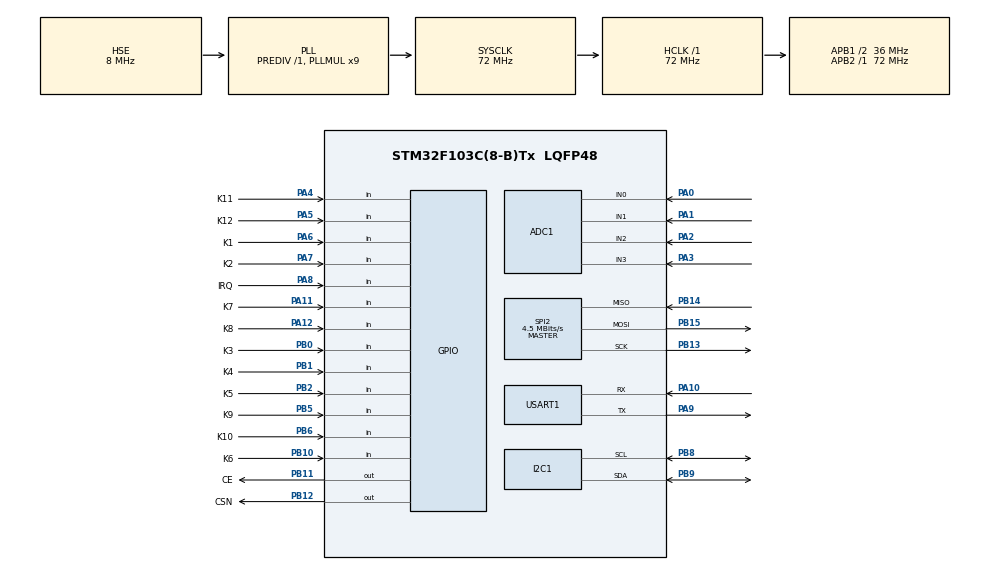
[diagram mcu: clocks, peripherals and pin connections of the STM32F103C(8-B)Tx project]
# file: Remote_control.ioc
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ADC1.Channel-0\#ChannelRegularConversion=ADC_CHANNEL_0
ADC1.Channel-1\#ChannelRegularConversion=ADC_CHANNEL_1
ADC1.Channel-2\#ChannelRegularConversion=ADC_CHANNEL_2
ADC1.Channel-3\#ChannelRegularConversion=ADC_CHANNEL_3
ADC1.ContinuousConvMode=ENABLE
ADC1.NbrOfConversion=4
ADC1.NbrOfConversionFlag=1
ADC1.Rank-0\#ChannelRegularConversion=1
ADC1.Rank-1\#ChannelRegularConversion=2
ADC1.Rank-2\#ChannelRegularConversion=3
ADC1.Rank-3\#ChannelRegularConversion=4
ADC1.SamplingTime-0\#ChannelRegularConversion=ADC_SAMPLETIME_55CYCLES_5
ADC1.SamplingTime-1\#ChannelRegularConversion=ADC_SAMPLETIME_55CYCLES_5
ADC1.SamplingTime-2\#ChannelRegularConversion=ADC_SAMPLETIME_55CYCLES_5
ADC1.SamplingTime-3\#ChannelRegularConversion=ADC_SAMPLETIME_55CYCLES_5
ADC1.master=1
Dma.ADC1.1.Direction=DMA_PERIPH_TO_MEMORY
Dma.ADC1.1.Instance=DMA1_Channel1
Dma.ADC1.1.MemDataAlignment=DMA_MDATAALIGN_HALFWORD
Dma.ADC1.1.MemInc=DMA_MINC_ENABLE
Dma.ADC1.1.Mode=DMA_CIRCULAR
Dma.ADC1.1.PeriphDataAlignment=DMA_PDATAALIGN_HALFWORD
Dma.ADC1.1.PeriphInc=DMA_PINC_DISABLE
Dma.ADC1.1.Priority=DMA_PRIORITY_LOW
Dma.Request0=USART1_RX
Dma.Request1=ADC1
Dma.USART1_RX.0.Direction=DMA_PERIPH_TO_MEMORY
Dma.USART1_RX.0.Instance=DMA1_Channel5
Dma.USART1_RX.0.MemDataAlignment=DMA_MDATAALIGN_BYTE
Dma.USART1_RX.0.MemInc=DMA_MINC_ENABLE
Dma.USART1_RX.0.Mode=DMA_CIRCULAR
Dma.USART1_RX.0.PeriphDataAlignment=DMA_PDATAALIGN_BYTE
Dma.USART1_RX.0.PeriphInc=DMA_PINC_DISABLE
Dma.USART1_RX.0.Priority=DMA_PRIORITY_LOW
I2C1.I2C_Mode=I2C_Fast
IWDG.Prescaler=IWDG_PRESCALER_16
IWDG.Reload=2500
Mcu.Family=STM32F1
Mcu.Name=STM32F103C(8-B)Tx
Mcu.Package=LQFP48
NVIC.DMA1_Channel1_IRQn=true\:0\:0\:false\:false\:true\:false\:true\:true
NVIC.DMA1_Channel5_IRQn=true\:0\:0\:false\:false\:true\:false\:true\:true
NVIC.PriorityGroup=NVIC_PRIORITYGROUP_4
NVIC.TIM1_UP_IRQn=true\:15\:0\:false\:false\:true\:true\:true\:true
NVIC.TIM2_IRQn=true\:0\:0\:false\:false\:true\:true\:true\:true
NVIC.USART1_IRQn=true\:0\:0\:false\:false\:true\:true\:true\:true
PA0-WKUP.Signal=ADCx_IN0
PA1.Signal=ADCx_IN1
PA10.Mode=Asynchronous
PA10.Signal=USART1_RX
PA11.GPIO_Label=K7
PA11.GPIO_Mode=GPIO_MODE_INPUT
PA11.GPIO_PuPd=GPIO_PULLUP
PA11.Signal=GPIO_Input
PA12.GPIO_Label=K8
PA12.GPIO_Mode=GPIO_MODE_INPUT
PA12.GPIO_PuPd=GPIO_PULLUP
PA12.Signal=GPIO_Input
PA13.Mode=Serial_Wire
PA13.Signal=SYS_JTMS-SWDIO
PA14.Mode=Serial_Wire
PA14.Signal=SYS_JTCK-SWCLK
PA2.Signal=ADCx_IN2
PA3.Signal=ADCx_IN3
PA4.GPIO_Label=K11
PA4.Signal=GPIO_Input
PA5.GPIO_Label=K12
PA5.Signal=GPIO_Input
PA6.GPIO_Label=K1
PA6.GPIO_Mode=GPIO_MODE_INPUT
PA6.GPIO_PuPd=GPIO_PULLUP
PA6.Signal=GPIO_Input
PA7.GPIO_Label=K2
PA7.GPIO_Mode=GPIO_MODE_INPUT
PA7.GPIO_PuPd=GPIO_PULLUP
PA7.Signal=GPIO_Input
PA8.GPIO_Label=IRQ
PA8.GPIO_Mode=GPIO_MODE_INPUT
PA8.GPIO_PuPd=GPIO_NOPULL
PA8.Signal=GPIO_Input
PA9.Mode=Asynchronous
PA9.Signal=USART1_TX
PB0.GPIO_Label=K3
PB0.GPIO_Mode=GPIO_MODE_INPUT
PB0.GPIO_PuPd=GPIO_PULLUP
PB0.Signal=GPIO_Input
PB1.GPIO_Label=K4
PB1.GPIO_Mode=GPIO_MODE_INPUT
PB1.GPIO_PuPd=GPIO_PULLUP
PB1.Signal=GPIO_Input
PB10.GPIO_Label=K6
PB10.GPIO_Mode=GPIO_MODE_INPUT
PB10.GPIO_PuPd=GPIO_PULLUP
PB10.Signal=GPIO_Input
PB11.GPIO_Label=CE
PB11.Signal=GPIO_Output
PB12.GPIO_Label=CSN
PB12.PinState=GPIO_PIN_SET
PB12.Signal=GPIO_Output
PB13.Mode=Full_Duplex_Master
PB13.Signal=SPI2_SCK
PB14.Mode=Full_Duplex_Master
PB14.Signal=SPI2_MISO
PB15.Mode=Full_Duplex_Master
PB15.Signal=SPI2_MOSI
PB2.GPIO_Label=K5
PB2.GPIO_Mode=GPIO_MODE_INPUT
PB2.GPIO_PuPd=GPIO_PULLUP
PB2.Signal=GPIO_Input
PB5.GPIO_Label=K9
PB5.GPIO_Mode=GPIO_MODE_INPUT
PB5.GPIO_PuPd=GPIO_PULLUP
PB5.Signal=GPIO_Input
PB6.GPIO_Label=K10
PB6.GPIO_Mode=GPIO_MODE_INPUT
PB6.GPIO_PuPd=GPIO_PULLUP
PB6.Signal=GPIO_Input
PB8.Mode=I2C
PB8.Signal=I2C1_SCL
PB9.Mode=I2C
PB9.Signal=I2C1_SDA
PD0-OSC_IN.Mode=HSE-External-Oscillator
PD0-OSC_IN.Signal=RCC_OSC_IN
PD1-OSC_OUT.Mode=HSE-External-Oscillator
PD1-OSC_OUT.Signal=RCC_OSC_OUT
ProjectManager.HeapSize=0x200
ProjectManager.StackSize=0x400
ProjectManager.TargetToolchain=MDK-ARM V5.32
RCC.ADCPresc=RCC_ADCPCLK2_DIV6
RCC.AHBFreq_Value=72000000
RCC.APB1CLKDivider=RCC_HCLK_DIV2
RCC.APB1Freq_Value=36000000
RCC.APB1TimFreq_Value=72000000
RCC.APB2Freq_Value=72000000
RCC.APB2TimFreq_Value=72000000
RCC.HCLKFreq_Value=72000000
RCC.PLLMUL=RCC_PLL_MUL9
RCC.PLLSourceVirtual=RCC_PLLSOURCE_HSE
RCC.SYSCLKFreq_VALUE=72000000
RCC.SYSCLKSource=RCC_SYSCLKSOURCE_PLLCLK
RCC.USBFreq_Value=72000000
SH.ADCx_IN0.0=ADC1_IN0,IN0
SH.ADCx_IN1.0=ADC1_IN1,IN1
SH.ADCx_IN2.0=ADC1_IN2,IN2
SH.ADCx_IN3.0=ADC1_IN3,IN3
SPI2.BaudRatePrescaler=SPI_BAUDRATEPRESCALER_8
SPI2.CalculateBaudRate=4.5 MBits/s
SPI2.Direction=SPI_DIRECTION_2LINES
SPI2.Mode=SPI_MODE_MASTER
SPI2.VirtualType=VM_MASTER
TIM1.Period=1000-1
TIM1.Prescaler=72-1
TIM2.Period=1000-1
TIM2.Prescaler=72-1
USART1.VirtualMode=VM_ASYNC
VP_IWDG_VS_IWDG.Mode=IWDG_Activate
VP_TIM1_VS_ClockSourceINT.Mode=Internal
VP_TIM2_VS_ClockSourceINT.Mode=Internal
board=custom

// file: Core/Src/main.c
/* USER CODE BEGIN Header */
/**
  ******************************************************************************
  * @file           : main.c
  * @brief          : Main program body
  ******************************************************************************
  * @attention
  *
  * Copyright (c) 2026 STMicroelectronics.
  * All rights reserved.
  *
  * This software is licensed under terms that can be found in the LICENSE file
  * in the root directory of this software component.
  * If no LICENSE file comes with this software, it is provided AS-IS.
  *
  ******************************************************************************
  */
/* USER CODE END Header */
#include "main.h"
#include "adc.h"
#include "dma.h"
#include "i2c.h"
#include "iwdg.h"
#include "spi.h"
#include "tim.h"
#include "usart.h"
#include "gpio.h"

void SystemClock_Config(void);

int main(void)
{

  /* MCU Configuration--------------------------------------------------------*/

  /* Reset of all peripherals, Initializes the Flash interface and the Systick. */
  HAL_Init();

  /* Configure the system clock */
  SystemClock_Config();

  /* Initialize all configured peripherals */
  MX_GPIO_Init();
  MX_DMA_Init();
  MX_IWDG_Init();
  MX_USART1_UART_Init();
  MX_ADC1_Init();
  MX_SPI2_Init();
  MX_TIM2_Init();
  MX_TIM1_Init();
  MX_I2C1_Init();

  /* Infinite loop */
  /* USER CODE BEGIN WHILE */
  app_init();
  while (1)
  {
      main_loop_task();
    /* USER CODE END WHILE */

  }
}

void SystemClock_Config(void)
{
  RCC_OscInitTypeDef RCC_OscInitStruct = {0};
  RCC_ClkInitTypeDef RCC_ClkInitStruct = {0};
  RCC_PeriphCLKInitTypeDef PeriphClkInit = {0};

  /** Initializes the RCC Oscillators according to the specified parameters
  * in the RCC_OscInitTypeDef structure.
  */
  RCC_OscInitStruct.OscillatorType = RCC_OSCILLATORTYPE_LSI|RCC_OSCILLATORTYPE_HSE;
  RCC_OscInitStruct.HSEState = RCC_HSE_ON;
  RCC_OscInitStruct.HSEPredivValue = RCC_HSE_PREDIV_DIV1;
  RCC_OscInitStruct.HSIState = RCC_HSI_ON;
  RCC_OscInitStruct.LSIState = RCC_LSI_ON;
  RCC_OscInitStruct.PLL.PLLState = RCC_PLL_ON;
  RCC_OscInitStruct.PLL.PLLSource = RCC_PLLSOURCE_HSE;
  RCC_OscInitStruct.PLL.PLLMUL = RCC_PLL_MUL9;
  if (HAL_RCC_OscConfig(&RCC_OscInitStruct) != HAL_OK)
  {
    Error_Handler();
  }

  /** Initializes the CPU, AHB and APB buses clocks
  */
  RCC_ClkInitStruct.ClockType = RCC_CLOCKTYPE_HCLK|RCC_CLOCKTYPE_SYSCLK
                              |RCC_CLOCKTYPE_PCLK1|RCC_CLOCKTYPE_PCLK2;
  RCC_ClkInitStruct.SYSCLKSource = RCC_SYSCLKSOURCE_PLLCLK;
  RCC_ClkInitStruct.AHBCLKDivider = RCC_SYSCLK_DIV1;
  RCC_ClkInitStruct.APB1CLKDivider = RCC_HCLK_DIV2;
  RCC_ClkInitStruct.APB2CLKDivider = RCC_HCLK_DIV1;

  if (HAL_RCC_ClockConfig(&RCC_ClkInitStruct, FLASH_LATENCY_2) != HAL_OK)
  {
    Error_Handler();
  }
  PeriphClkInit.PeriphClockSelection = RCC_PERIPHCLK_ADC;
  PeriphClkInit.AdcClockSelection = RCC_ADCPCLK2_DIV6;
  if (HAL_RCCEx_PeriphCLKConfig(&PeriphClkInit) != HAL_OK)
  {
    Error_Handler();
  }
}

void Error_Handler(void)
{
  __disable_irq();
  while (1)
  {
  }
}
